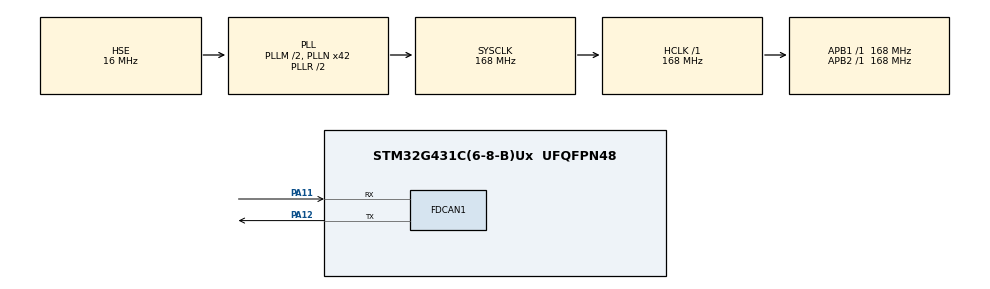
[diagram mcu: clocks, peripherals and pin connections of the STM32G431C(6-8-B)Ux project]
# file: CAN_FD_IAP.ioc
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CRC.CRCLength=CRC_POLYLENGTH_8B
CRC.DefaultPolynomialUse=DEFAULT_POLYNOMIAL_DISABLE
FDCAN1.CalculateBaudRateNominal=1000000
FDCAN1.CalculateTimeBitNominal=1000
FDCAN1.CalculateTimeQuantumNominal=17.857142857142858
FDCAN1.DataPrescaler=1
FDCAN1.DataSyncJumpWidth=4
FDCAN1.DataTimeSeg1=16
FDCAN1.DataTimeSeg2=4
FDCAN1.FrameFormat=FDCAN_FRAME_FD_BRS
FDCAN1.NominalPrescaler=3
FDCAN1.NominalSyncJumpWidth=4
FDCAN1.NominalTimeSeg1=48
FDCAN1.NominalTimeSeg2=7
Mcu.Family=STM32G4
Mcu.Name=STM32G431C(6-8-B)Ux
Mcu.Package=UFQFPN48
NVIC.FDCAN1_IT0_IRQn=true\:0\:0\:false\:false\:true\:true\:true\:true
NVIC.FDCAN1_IT1_IRQn=true\:0\:0\:false\:false\:true\:true\:true\:true
NVIC.PriorityGroup=NVIC_PRIORITYGROUP_4
PA11.Mode=FDCAN_Activate
PA11.Signal=FDCAN1_RX
PA12.Mode=FDCAN_Activate
PA12.Signal=FDCAN1_TX
PA13.Mode=Serial_Wire
PA13.Signal=SYS_JTMS-SWDIO
PA14.Mode=Serial_Wire
PA14.Signal=SYS_JTCK-SWCLK
PF0-OSC_IN.Mode=HSE-External-Oscillator
PF0-OSC_IN.Signal=RCC_OSC_IN
PF1-OSC_OUT.Mode=HSE-External-Oscillator
PF1-OSC_OUT.Signal=RCC_OSC_OUT
ProjectManager.HeapSize=0x200
ProjectManager.StackSize=0x400
ProjectManager.TargetToolchain=CMake
RCC.ADC12Freq_Value=168000000
RCC.AHBFreq_Value=168000000
RCC.APB1Freq_Value=168000000
RCC.APB1TimFreq_Value=168000000
RCC.APB2Freq_Value=168000000
RCC.APB2TimFreq_Value=168000000
RCC.CortexFreq_Value=168000000
RCC.EXTERNAL_CLOCK_VALUE=12288000
RCC.HCLKFreq_Value=168000000
RCC.HSE_VALUE=16000000
RCC.HSI48_VALUE=48000000
RCC.HSI_VALUE=16000000
RCC.LSE_VALUE=32768
RCC.PLLM=RCC_PLLM_DIV2
RCC.PLLN=42
RCC.PLLSourceVirtual=RCC_PLLSOURCE_HSE
RCC.SYSCLKFreq_VALUE=168000000
RCC.SYSCLKSource=RCC_SYSCLKSOURCE_PLLCLK
RCC.USBFreq_Value=168000000
RCC.VCOOutputFreq_Value=336000000
VP_CRC_VS_CRC.Mode=CRC_Activate
VP_SYS_VS_DBSignals.Mode=DisableDeadBatterySignals
board=custom

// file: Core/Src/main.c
/* USER CODE BEGIN Header */
/**
  ******************************************************************************
  * @file           : main.c
  * @brief          : Main program body
  ******************************************************************************
  * @attention
  *
  * Copyright (c) 2026 STMicroelectronics.
  * All rights reserved.
  *
  * This software is licensed under terms that can be found in the LICENSE file
  * in the root directory of this software component.
  * If no LICENSE file comes with this software, it is provided AS-IS.
  *
  ******************************************************************************
  */
/* USER CODE END Header */
#include "main.h"
#include "fdcan.h"

/* USER CODE BEGIN Includes */
/* 板级时钟配置、Bootloader 协议核心和 FDCAN 传输适配层的项目接口。 */
#include "board_config.h"
#include "bootloader.h"
#include "boot_port_can_stm32g4.h"
/* USER CODE END Includes */

/* USER CODE BEGIN PV */
/* 当前没有需要在 main.c 中长期保存的用户态全局变量。 */

/* USER CODE END PV */

/* 配置 HSE、PLL、SYSCLK、AHB 和 APB 时钟树。 */
void SystemClock_Config(void);
/* USER CODE BEGIN PFP */
/* 用户自定义函数原型为空；Bootloader 接口由对应头文件提供。 */
/* USER CODE END PFP */

/* USER CODE BEGIN 0 */
/* 预留可被 CubeMX 保留的用户辅助代码区；当前无需额外辅助函数。 */
/* USER CODE END 0 */

int main(void)
{
  /* 固件主入口：初始化 HAL、时钟、FDCAN 和 Bootloader，然后持续轮询任务。 */

  /* USER CODE BEGIN 1 */
  /* 复位后的最早用户初始化区；当前初始化统一放在 HAL 和时钟完成之后。 */
  /* USER CODE END 1 */

  /* MCU Configuration--------------------------------------------------------*/

  /* Reset of all peripherals, Initializes the Flash interface and the Systick. */
  HAL_Init();

  /* USER CODE BEGIN Init */
  /* HAL_Init() 完成后、系统时钟切换前的用户初始化区；当前不执行协议操作。 */
  /* USER CODE END Init */

  /* Configure the system clock */
  SystemClock_Config();

  /* USER CODE BEGIN SysInit */
  /* 系统时钟配置完成后的用户区；外设启动和过滤器配置放入下方 USER CODE 2。 */
  /* USER CODE END SysInit */

  /* Initialize all configured peripherals */
  /* FDCAN MSP initializes GPIOA and PA11/PA12 itself.  The generated
     MX_GPIO_Init() only enabled unused GPIO clocks, so it is omitted here. */
  MX_FDCAN1_Init();
  /* USER CODE BEGIN 2 */
  /* 配置接收过滤器，使控制帧、DATA 帧和节点间帧进入统一接收路径。 */
  BootPort_CAN_Filter_Init();

  /* 注册节点号、发送回调、发送排空回调和底层 FDCAN 句柄。 */
  Boot_Init(1,BootPort_CAN_Send,BootPort_CAN_Flush,&hfdcan1);
  /* 根据持久化元数据判断是否可以安全跳转到 APP。 */
  if (Boot_ShouldJumpApp() != 0U) {
    Boot_JumpApp();
  }
  /* 启动 FDCAN 外设并打开 FIFO0 新消息中断。 */
  if (HAL_FDCAN_Start(&hfdcan1) != HAL_OK) {
    Error_Handler();
  }
  if (HAL_FDCAN_ActivateNotification(&hfdcan1, FDCAN_IT_RX_FIFO0_NEW_MESSAGE,0) != HAL_OK) {
    Error_Handler();
  }

  /* USER CODE END 2 */

  /* Infinite loop */
  /* USER CODE BEGIN WHILE */
  while (1)
  {
    /* 每轮先推进经典 CAN 分片发送，再处理协议队列和 Flash 状态机。 */
    BootPort_CAN_Task(&hfdcan1);
    Boot_Task();
    /* USER CODE END WHILE */

    /* USER CODE BEGIN 3 */
    /* 当前循环没有额外的用户逻辑；Bootloader 任务已在上方完成。 */
  }
  /* USER CODE END 3 */
}

void SystemClock_Config(void)
{
  /* 振荡器和 PLL 参数结构体，按 16 MHz HSE 配置固定 PLLN。 */
  RCC_OscInitTypeDef RCC_OscInitStruct = {0};
  /* CPU、AHB、APB 总线时钟分频结构体。 */
  RCC_ClkInitTypeDef RCC_ClkInitStruct = {0};

  /** Configure the main internal regulator output voltage
  */
  HAL_PWREx_ControlVoltageScaling(PWR_REGULATOR_VOLTAGE_SCALE1_BOOST);

  /** Initializes the RCC Oscillators according to the specified parameters
  * in the RCC_OscInitTypeDef structure.
  */
  RCC_OscInitStruct.OscillatorType = RCC_OSCILLATORTYPE_HSE;
  RCC_OscInitStruct.HSEState = RCC_HSE_ON;
  RCC_OscInitStruct.PLL.PLLState = RCC_PLL_ON;
  RCC_OscInitStruct.PLL.PLLSource = RCC_PLLSOURCE_HSE;
  /*
   * 16 MHz 晶振生成精确的 168 MHz SYSCLK/FDCAN 内核时钟：
   * 16 / PLLM(2) = 8 MHz VCO 输入，× PLLN(42) = 336 MHz VCO，
   * / PLLR(2) = 168 MHz SYSCLK。
   * PLLN 与 board_config.h 的 BOARD_HSE_HZ 相互绑定：该文件已把外部晶振
   * 限定为 16 MHz，换晶振时会先在那里编译失败，不会产出时钟错误的固件。
   */
  RCC_OscInitStruct.PLL.PLLM = RCC_PLLM_DIV2;
  RCC_OscInitStruct.PLL.PLLN = 42;
  RCC_OscInitStruct.PLL.PLLP = RCC_PLLP_DIV2;
  RCC_OscInitStruct.PLL.PLLQ = RCC_PLLQ_DIV2;
  RCC_OscInitStruct.PLL.PLLR = RCC_PLLR_DIV2;
  if (HAL_RCC_OscConfig(&RCC_OscInitStruct) != HAL_OK)
  {
    Error_Handler();
  }

  /** Initializes the CPU, AHB and APB buses clocks
  */
  RCC_ClkInitStruct.ClockType = RCC_CLOCKTYPE_HCLK|RCC_CLOCKTYPE_SYSCLK
                              |RCC_CLOCKTYPE_PCLK1|RCC_CLOCKTYPE_PCLK2;
  RCC_ClkInitStruct.SYSCLKSource = RCC_SYSCLKSOURCE_PLLCLK;
  RCC_ClkInitStruct.AHBCLKDivider = RCC_SYSCLK_DIV1;
  RCC_ClkInitStruct.APB1CLKDivider = RCC_HCLK_DIV1;
  RCC_ClkInitStruct.APB2CLKDivider = RCC_HCLK_DIV1;

  if (HAL_RCC_ClockConfig(&RCC_ClkInitStruct, FLASH_LATENCY_4) != HAL_OK)
  {
    Error_Handler();
  }
}

void Error_Handler(void)
{
  /* HAL 初始化失败时关闭中断并停机，防止在未配置硬件上继续运行。 */
  /* USER CODE BEGIN Error_Handler_Debug */
  /* 该用户区适合增加板级故障指示，但不能阻塞或改变停机安全语义。 */
  /* User can add his own implementation to report the HAL error return state */
  __disable_irq();
  while (1)
  {
  }
  /* USER CODE END Error_Handler_Debug */
}
#ifdef USE_FULL_ASSERT
/**
  * @brief  Reports the name of the source file and the source line number
  *         where the assert_param error has occurred.
  * @param  file: pointer to the source file name
  * @param  line: assert_param error line source number
  * @retval None
  */
void assert_failed(uint8_t *file, uint32_t line)
{
  /* 参数断言失败入口；当前版本保留 file/line 供调试器查看。 */
  /* USER CODE BEGIN 6 */
  /* 断言参数仅用于调试定位；当前不通过串口或 CAN 输出故障文本。 */
  /* User can add his own implementation to report the file name and line number,
     ex: printf("Wrong parameters value: file %s on line %d\r\n", file, line) */
  /* USER CODE END 6 */
}
#endif /* USE_FULL_ASSERT */
